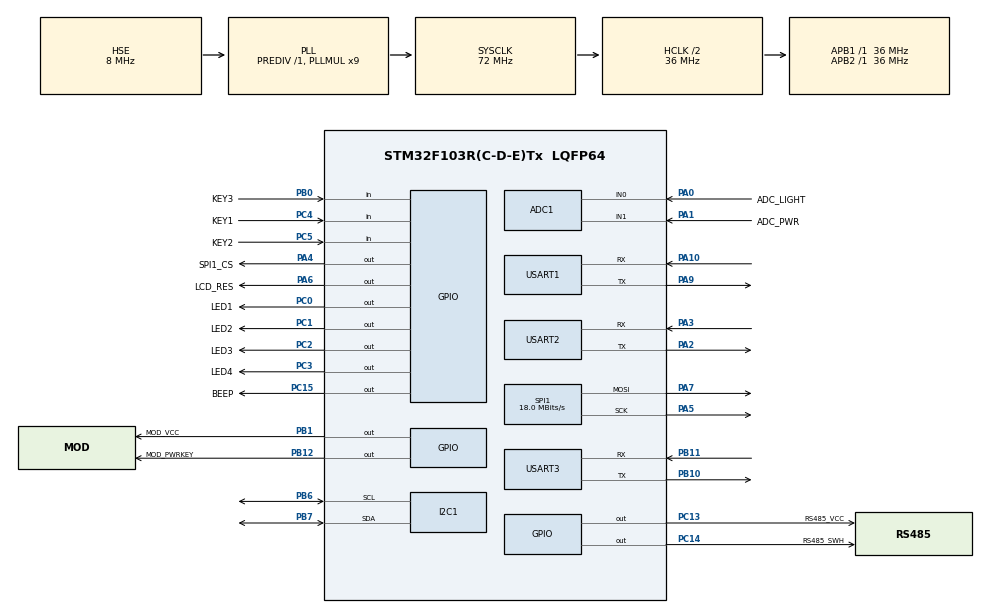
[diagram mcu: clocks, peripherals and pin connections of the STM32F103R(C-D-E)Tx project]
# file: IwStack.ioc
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ADC1.Channel-0\#ChannelRegularConversion=ADC_CHANNEL_1
ADC1.NbrOfConversionFlag=1
ADC1.Rank-0\#ChannelRegularConversion=1
ADC1.SamplingTime-0\#ChannelRegularConversion=ADC_SAMPLETIME_1CYCLE_5
ADC1.master=1
Dma.Request0=USART3_RX
Dma.USART3_RX.0.Direction=DMA_PERIPH_TO_MEMORY
Dma.USART3_RX.0.Instance=DMA1_Channel3
Dma.USART3_RX.0.MemDataAlignment=DMA_MDATAALIGN_BYTE
Dma.USART3_RX.0.MemInc=DMA_MINC_ENABLE
Dma.USART3_RX.0.Mode=DMA_CIRCULAR
Dma.USART3_RX.0.PeriphDataAlignment=DMA_PDATAALIGN_BYTE
Dma.USART3_RX.0.PeriphInc=DMA_PINC_DISABLE
Dma.USART3_RX.0.Priority=DMA_PRIORITY_LOW
FREERTOS.HEAP_NUMBER=3
FREERTOS.INCLUDE_xTaskAbortDelay=1
FREERTOS.Tasks01=myTask_led,25,128,Task01_Led,Default,NULL,Static,myTask_ledBuffer,myTask_ledControlBlock;myTask_net,27,1024,Task03_Net,Default,NULL,Static,myTask_netBuffer,myTask_netControlBlock;myTask_app,28,1024,Task04_App,Default,NULL,Static,myTask_appBuffer,myTask_appControlBlock
FREERTOS.configTOTAL_HEAP_SIZE=0x200
FREERTOS.configUSE_IDLE_HOOK=1
Mcu.Family=STM32F1
Mcu.Name=STM32F103R(C-D-E)Tx
Mcu.Package=LQFP64
NVIC.DMA1_Channel3_IRQn=true\:5\:0\:false\:false\:true\:true\:false\:true
NVIC.PriorityGroup=NVIC_PRIORITYGROUP_4
NVIC.USART3_IRQn=true\:5\:0\:false\:false\:true\:true\:true\:true
PA0-WKUP.GPIO_Label=ADC_LIGHT
PA0-WKUP.Signal=ADCx_IN0
PA1.GPIO_Label=ADC_PWR
PA1.Signal=ADCx_IN1
PA10.Mode=Asynchronous
PA10.Signal=USART1_RX
PA13.Mode=Serial_Wire
PA13.Signal=SYS_JTMS-SWDIO
PA14.Mode=Serial_Wire
PA14.Signal=SYS_JTCK-SWCLK
PA2.Mode=Asynchronous
PA2.Signal=USART2_TX
PA3.Mode=Asynchronous
PA3.Signal=USART2_RX
PA4.GPIO_Label=SPI1_CS
PA4.Signal=GPIO_Output
PA5.Mode=TX_Only_Simplex_Unidirect_Master
PA5.Signal=SPI1_SCK
PA6.GPIO_Label=LCD_RES
PA6.Signal=GPIO_Output
PA7.Mode=TX_Only_Simplex_Unidirect_Master
PA7.Signal=SPI1_MOSI
PA9.Mode=Asynchronous
PA9.Signal=USART1_TX
PB0.GPIO_Label=KEY3
PB0.Signal=GPIO_Input
PB1.GPIO_Label=MOD_VCC
PB1.Signal=GPIO_Output
PB10.Mode=Asynchronous
PB10.Signal=USART3_TX
PB11.Mode=Asynchronous
PB11.Signal=USART3_RX
PB12.GPIO_Label=MOD_PWRKEY
PB12.Signal=GPIO_Output
PB6.Mode=I2C
PB6.Signal=I2C1_SCL
PB7.Mode=I2C
PB7.Signal=I2C1_SDA
PC0.GPIO_Label=LED1
PC0.Signal=GPIO_Output
PC1.GPIO_Label=LED2
PC1.Signal=GPIO_Output
PC13-TAMPER-RTC.GPIO_Label=RS485_VCC
PC13-TAMPER-RTC.Signal=GPIO_Output
PC14-OSC32_IN.GPIO_Label=RS485_SWH
PC14-OSC32_IN.Signal=GPIO_Output
PC15-OSC32_OUT.GPIO_Label=BEEP
PC15-OSC32_OUT.Signal=GPIO_Output
PC2.GPIO_Label=LED3
PC2.Signal=GPIO_Output
PC3.GPIO_Label=LED4
PC3.Signal=GPIO_Output
PC4.GPIO_Label=KEY1
PC4.Signal=GPIO_Input
PC5.GPIO_Label=KEY2
PC5.Signal=GPIO_Input
PD0-OSC_IN.Mode=HSE-External-Oscillator
PD0-OSC_IN.Signal=RCC_OSC_IN
PD1-OSC_OUT.Mode=HSE-External-Oscillator
PD1-OSC_OUT.Signal=RCC_OSC_OUT
ProjectManager.HeapSize=0x4000
ProjectManager.StackSize=0x400
ProjectManager.TargetToolchain=MDK-ARM V5
RCC.ADCPresc=RCC_ADCPCLK2_DIV4
RCC.AHBCLKDivider=RCC_SYSCLK_DIV2
RCC.AHBFreq_Value=36000000
RCC.APB1Freq_Value=36000000
RCC.APB1TimFreq_Value=36000000
RCC.APB2Freq_Value=36000000
RCC.APB2TimFreq_Value=36000000
RCC.HCLKFreq_Value=36000000
RCC.PLLMUL=RCC_PLL_MUL9
RCC.PLLSourceVirtual=RCC_PLLSOURCE_HSE
RCC.SYSCLKFreq_VALUE=72000000
RCC.SYSCLKSource=RCC_SYSCLKSOURCE_PLLCLK
RCC.USBFreq_Value=72000000
SH.ADCx_IN0.0=ADC1_IN0,IN0
SH.ADCx_IN1.0=ADC1_IN1,IN1
SPI1.BaudRatePrescaler=SPI_BAUDRATEPRESCALER_2
SPI1.CalculateBaudRate=18.0 MBits/s
SPI1.Direction=SPI_DIRECTION_2LINES
SPI1.Mode=SPI_MODE_MASTER
SPI1.VirtualType=VM_MASTER
USART1.VirtualMode=VM_ASYNC
USART2.VirtualMode=VM_ASYNC
USART3.VirtualMode=VM_ASYNC
VP_FREERTOS_VS_CMSIS_V2.Mode=CMSIS_V2
board=custom

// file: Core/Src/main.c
/* USER CODE BEGIN Header */
/**
  ******************************************************************************
  * @file           : main.c
  * @brief          : Main program body
  ******************************************************************************
  * @attention
  *
  * <h2><center>&copy; Copyright (c) 2021 STMicroelectronics.
  * All rights reserved.</center></h2>
  *
  * This software component is licensed by ST under BSD 3-Clause license,
  * the "License"; You may not use this file except in compliance with the
  * License. You may obtain a copy of the License at:
  *                        opensource.org/licenses/BSD-3-Clause
  *
  ******************************************************************************
  */
/* USER CODE END Header */
#include "main.h"
#include "cmsis_os.h"

/* USER CODE BEGIN Includes */
#include "uart1_print.h"
#include "chip.h"
/* USER CODE END Includes */

typedef StaticTask_t osStaticThreadDef_t;

ADC_HandleTypeDef hadc1;

I2C_HandleTypeDef hi2c1;

SPI_HandleTypeDef hspi1;

UART_HandleTypeDef huart1;
UART_HandleTypeDef huart2;
UART_HandleTypeDef huart3;
DMA_HandleTypeDef hdma_usart3_rx;

/* Definitions for myTask_led */
osThreadId_t myTask_ledHandle;
uint32_t myTask_ledBuffer[ 128 ];
osStaticThreadDef_t myTask_ledControlBlock;
const osThreadAttr_t myTask_led_attributes = {
  .name = "myTask_led",
  .stack_mem = &myTask_ledBuffer[0],
  .stack_size = sizeof(myTask_ledBuffer),
  .cb_mem = &myTask_ledControlBlock,
  .cb_size = sizeof(myTask_ledControlBlock),
  .priority = (osPriority_t) osPriorityNormal1,
};
/* Definitions for myTask_net */
osThreadId_t myTask_netHandle;
uint32_t myTask_netBuffer[ 1024 ];
osStaticThreadDef_t myTask_netControlBlock;
const osThreadAttr_t myTask_net_attributes = {
  .name = "myTask_net",
  .stack_mem = &myTask_netBuffer[0],
  .stack_size = sizeof(myTask_netBuffer),
  .cb_mem = &myTask_netControlBlock,
  .cb_size = sizeof(myTask_netControlBlock),
  .priority = (osPriority_t) osPriorityNormal3,
};
/* Definitions for myTask_app */
osThreadId_t myTask_appHandle;
uint32_t myTask_appBuffer[ 1024 ];
osStaticThreadDef_t myTask_appControlBlock;
const osThreadAttr_t myTask_app_attributes = {
  .name = "myTask_app",
  .stack_mem = &myTask_appBuffer[0],
  .stack_size = sizeof(myTask_appBuffer),
  .cb_mem = &myTask_appControlBlock,
  .cb_size = sizeof(myTask_appControlBlock),
  .priority = (osPriority_t) osPriorityNormal4,
};

void SystemClock_Config(void);
static void MX_GPIO_Init(void);
static void MX_DMA_Init(void);
static void MX_ADC1_Init(void);
static void MX_I2C1_Init(void);
static void MX_SPI1_Init(void);
static void MX_USART1_UART_Init(void);
static void MX_USART2_UART_Init(void);
static void MX_USART3_UART_Init(void);
void Task01_Led(void *argument);
void Task03_Net(void *argument);
void Task04_App(void *argument);

int main(void)
{

  /* MCU Configuration--------------------------------------------------------*/

  /* Reset of all peripherals, Initializes the Flash interface and the Systick. */
  HAL_Init();

  /* Configure the system clock */
  SystemClock_Config();

  /* Initialize all configured peripherals */
  MX_GPIO_Init();
  MX_DMA_Init();
  MX_ADC1_Init();
  MX_I2C1_Init();
  MX_SPI1_Init();
  MX_USART1_UART_Init();
  MX_USART2_UART_Init();
  MX_USART3_UART_Init();
  /* USER CODE BEGIN 2 */

    USART1_Printf(	"ChipID:%.24s\r\n", CHIP_GetId()	);

  /* USER CODE END 2 */

  /* Init scheduler */
  osKernelInitialize();

  /* Create the thread(s) */
  /* creation of myTask_led */
  myTask_ledHandle = osThreadNew(Task01_Led, NULL, &myTask_led_attributes);

  /* creation of myTask_net */
  myTask_netHandle = osThreadNew(Task03_Net, NULL, &myTask_net_attributes);

  /* creation of myTask_app */
  myTask_appHandle = osThreadNew(Task04_App, NULL, &myTask_app_attributes);

  /* Start scheduler */
  osKernelStart();

  /* We should never get here as control is now taken by the scheduler */
  /* Infinite loop */
    while (1)
    {

    }
}

void SystemClock_Config(void)
{
  RCC_OscInitTypeDef RCC_OscInitStruct = {0};
  RCC_ClkInitTypeDef RCC_ClkInitStruct = {0};
  RCC_PeriphCLKInitTypeDef PeriphClkInit = {0};

  /** Initializes the RCC Oscillators according to the specified parameters
  * in the RCC_OscInitTypeDef structure.
  */
  RCC_OscInitStruct.OscillatorType = RCC_OSCILLATORTYPE_HSE;
  RCC_OscInitStruct.HSEState = RCC_HSE_ON;
  RCC_OscInitStruct.HSEPredivValue = RCC_HSE_PREDIV_DIV1;
  RCC_OscInitStruct.HSIState = RCC_HSI_ON;
  RCC_OscInitStruct.PLL.PLLState = RCC_PLL_ON;
  RCC_OscInitStruct.PLL.PLLSource = RCC_PLLSOURCE_HSE;
  RCC_OscInitStruct.PLL.PLLMUL = RCC_PLL_MUL9;
  if (HAL_RCC_OscConfig(&RCC_OscInitStruct) != HAL_OK)
  {
    Error_Handler();
  }
  /** Initializes the CPU, AHB and APB buses clocks
  */
  RCC_ClkInitStruct.ClockType = RCC_CLOCKTYPE_HCLK|RCC_CLOCKTYPE_SYSCLK
                              |RCC_CLOCKTYPE_PCLK1|RCC_CLOCKTYPE_PCLK2;
  RCC_ClkInitStruct.SYSCLKSource = RCC_SYSCLKSOURCE_PLLCLK;
  RCC_ClkInitStruct.AHBCLKDivider = RCC_SYSCLK_DIV2;
  RCC_ClkInitStruct.APB1CLKDivider = RCC_HCLK_DIV1;
  RCC_ClkInitStruct.APB2CLKDivider = RCC_HCLK_DIV1;

  if (HAL_RCC_ClockConfig(&RCC_ClkInitStruct, FLASH_LATENCY_2) != HAL_OK)
  {
    Error_Handler();
  }
  PeriphClkInit.PeriphClockSelection = RCC_PERIPHCLK_ADC;
  PeriphClkInit.AdcClockSelection = RCC_ADCPCLK2_DIV4;
  if (HAL_RCCEx_PeriphCLKConfig(&PeriphClkInit) != HAL_OK)
  {
    Error_Handler();
  }
}

static void MX_ADC1_Init(void)
{

  ADC_ChannelConfTypeDef sConfig = {0};

  /** Common config
  */
  hadc1.Instance = ADC1;
  hadc1.Init.ScanConvMode = ADC_SCAN_DISABLE;
  hadc1.Init.ContinuousConvMode = DISABLE;
  hadc1.Init.DiscontinuousConvMode = DISABLE;
  hadc1.Init.ExternalTrigConv = ADC_SOFTWARE_START;
  hadc1.Init.DataAlign = ADC_DATAALIGN_RIGHT;
  hadc1.Init.NbrOfConversion = 1;
  if (HAL_ADC_Init(&hadc1) != HAL_OK)
  {
    Error_Handler();
  }
  /** Configure Regular Channel
  */
  sConfig.Channel = ADC_CHANNEL_0;
  sConfig.Rank = ADC_REGULAR_RANK_1;
  sConfig.SamplingTime = ADC_SAMPLETIME_1CYCLE_5;
  if (HAL_ADC_ConfigChannel(&hadc1, &sConfig) != HAL_OK)
  {
    Error_Handler();
  }

}

static void MX_I2C1_Init(void)
{

  hi2c1.Instance = I2C1;
  hi2c1.Init.ClockSpeed = 100000;
  hi2c1.Init.DutyCycle = I2C_DUTYCYCLE_2;
  hi2c1.Init.OwnAddress1 = 0;
  hi2c1.Init.AddressingMode = I2C_ADDRESSINGMODE_7BIT;
  hi2c1.Init.DualAddressMode = I2C_DUALADDRESS_DISABLE;
  hi2c1.Init.OwnAddress2 = 0;
  hi2c1.Init.GeneralCallMode = I2C_GENERALCALL_DISABLE;
  hi2c1.Init.NoStretchMode = I2C_NOSTRETCH_DISABLE;
  if (HAL_I2C_Init(&hi2c1) != HAL_OK)
  {
    Error_Handler();
  }

}

static void MX_SPI1_Init(void)
{

  /* SPI1 parameter configuration*/
  hspi1.Instance = SPI1;
  hspi1.Init.Mode = SPI_MODE_MASTER;
  hspi1.Init.Direction = SPI_DIRECTION_2LINES;
  hspi1.Init.DataSize = SPI_DATASIZE_8BIT;
  hspi1.Init.CLKPolarity = SPI_POLARITY_LOW;
  hspi1.Init.CLKPhase = SPI_PHASE_1EDGE;
  hspi1.Init.NSS = SPI_NSS_SOFT;
  hspi1.Init.BaudRatePrescaler = SPI_BAUDRATEPRESCALER_2;
  hspi1.Init.FirstBit = SPI_FIRSTBIT_MSB;
  hspi1.Init.TIMode = SPI_TIMODE_DISABLE;
  hspi1.Init.CRCCalculation = SPI_CRCCALCULATION_DISABLE;
  hspi1.Init.CRCPolynomial = 10;
  if (HAL_SPI_Init(&hspi1) != HAL_OK)
  {
    Error_Handler();
  }

}

static void MX_USART1_UART_Init(void)
{

  huart1.Instance = USART1;
  huart1.Init.BaudRate = 115200;
  huart1.Init.WordLength = UART_WORDLENGTH_8B;
  huart1.Init.StopBits = UART_STOPBITS_1;
  huart1.Init.Parity = UART_PARITY_NONE;
  huart1.Init.Mode = UART_MODE_TX_RX;
  huart1.Init.HwFlowCtl = UART_HWCONTROL_NONE;
  huart1.Init.OverSampling = UART_OVERSAMPLING_16;
  if (HAL_UART_Init(&huart1) != HAL_OK)
  {
    Error_Handler();
  }

}

static void MX_USART2_UART_Init(void)
{

  huart2.Instance = USART2;
  huart2.Init.BaudRate = 115200;
  huart2.Init.WordLength = UART_WORDLENGTH_8B;
  huart2.Init.StopBits = UART_STOPBITS_1;
  huart2.Init.Parity = UART_PARITY_NONE;
  huart2.Init.Mode = UART_MODE_TX_RX;
  huart2.Init.HwFlowCtl = UART_HWCONTROL_NONE;
  huart2.Init.OverSampling = UART_OVERSAMPLING_16;
  if (HAL_UART_Init(&huart2) != HAL_OK)
  {
    Error_Handler();
  }

}

static void MX_USART3_UART_Init(void)
{

  huart3.Instance = USART3;
  huart3.Init.BaudRate = 115200;
  huart3.Init.WordLength = UART_WORDLENGTH_8B;
  huart3.Init.StopBits = UART_STOPBITS_1;
  huart3.Init.Parity = UART_PARITY_NONE;
  huart3.Init.Mode = UART_MODE_TX_RX;
  huart3.Init.HwFlowCtl = UART_HWCONTROL_NONE;
  huart3.Init.OverSampling = UART_OVERSAMPLING_16;
  if (HAL_UART_Init(&huart3) != HAL_OK)
  {
    Error_Handler();
  }

}

static void MX_DMA_Init(void)
{

  /* DMA controller clock enable */
  __HAL_RCC_DMA1_CLK_ENABLE();

  /* DMA interrupt init */
  /* DMA1_Channel3_IRQn interrupt configuration */
  HAL_NVIC_SetPriority(DMA1_Channel3_IRQn, 5, 0);
  HAL_NVIC_EnableIRQ(DMA1_Channel3_IRQn);

}

static void MX_GPIO_Init(void)
{
  GPIO_InitTypeDef GPIO_InitStruct = {0};

  /* GPIO Ports Clock Enable */
  __HAL_RCC_GPIOC_CLK_ENABLE();
  __HAL_RCC_GPIOD_CLK_ENABLE();
  __HAL_RCC_GPIOA_CLK_ENABLE();
  __HAL_RCC_GPIOB_CLK_ENABLE();

  /*Configure GPIO pin Output Level */
  HAL_GPIO_WritePin(GPIOC, RS485_VCC_Pin|RS485_SWH_Pin|BEEP_Pin|LED1_Pin
                          |LED2_Pin|LED3_Pin|LED4_Pin, GPIO_PIN_RESET);

  /*Configure GPIO pin Output Level */
  HAL_GPIO_WritePin(GPIOA, SPI1_CS_Pin|LCD_RES_Pin, GPIO_PIN_RESET);

  /*Configure GPIO pin Output Level */
  HAL_GPIO_WritePin(GPIOB, MOD_VCC_Pin|MOD_PWRKEY_Pin, GPIO_PIN_RESET);

  /*Configure GPIO pins : RS485_VCC_Pin RS485_SWH_Pin BEEP_Pin LED1_Pin
                           LED2_Pin LED3_Pin LED4_Pin */
  GPIO_InitStruct.Pin = RS485_VCC_Pin|RS485_SWH_Pin|BEEP_Pin|LED1_Pin
                          |LED2_Pin|LED3_Pin|LED4_Pin;
  GPIO_InitStruct.Mode = GPIO_MODE_OUTPUT_PP;
  GPIO_InitStruct.Pull = GPIO_NOPULL;
  GPIO_InitStruct.Speed = GPIO_SPEED_FREQ_LOW;
  HAL_GPIO_Init(GPIOC, &GPIO_InitStruct);

  /*Configure GPIO pins : SPI1_CS_Pin LCD_RES_Pin */
  GPIO_InitStruct.Pin = SPI1_CS_Pin|LCD_RES_Pin;
  GPIO_InitStruct.Mode = GPIO_MODE_OUTPUT_PP;
  GPIO_InitStruct.Pull = GPIO_NOPULL;
  GPIO_InitStruct.Speed = GPIO_SPEED_FREQ_LOW;
  HAL_GPIO_Init(GPIOA, &GPIO_InitStruct);

  /*Configure GPIO pins : KEY1_Pin KEY2_Pin */
  GPIO_InitStruct.Pin = KEY1_Pin|KEY2_Pin;
  GPIO_InitStruct.Mode = GPIO_MODE_INPUT;
  GPIO_InitStruct.Pull = GPIO_NOPULL;
  HAL_GPIO_Init(GPIOC, &GPIO_InitStruct);

  /*Configure GPIO pin : KEY3_Pin */
  GPIO_InitStruct.Pin = KEY3_Pin;
  GPIO_InitStruct.Mode = GPIO_MODE_INPUT;
  GPIO_InitStruct.Pull = GPIO_NOPULL;
  HAL_GPIO_Init(KEY3_GPIO_Port, &GPIO_InitStruct);

  /*Configure GPIO pins : MOD_VCC_Pin MOD_PWRKEY_Pin */
  GPIO_InitStruct.Pin = MOD_VCC_Pin|MOD_PWRKEY_Pin;
  GPIO_InitStruct.Mode = GPIO_MODE_OUTPUT_PP;
  GPIO_InitStruct.Pull = GPIO_NOPULL;
  GPIO_InitStruct.Speed = GPIO_SPEED_FREQ_LOW;
  HAL_GPIO_Init(GPIOB, &GPIO_InitStruct);

}

void Task01_Led(void *argument)
{
  /* USER CODE BEGIN 5 */
    /* Infinite loop */

    extern 	void TASK_Led ( void const * argument );
    TASK_Led ( argument );

  /* USER CODE END 5 */
}

void Task03_Net(void *argument)
{
  /* USER CODE BEGIN Task03_Net */
    /* Infinite loop */

    extern 	void TASK_Net ( void const * argument );
    TASK_Net (  argument );
    ///	while(1)  osDelay ( 200 );

  /* USER CODE END Task03_Net */
}

void Task04_App(void *argument)
{
  /* USER CODE BEGIN Task04_App */
    /* Infinite loop */

    extern 	void TASK_App ( void const * argument );

    TASK_App ( argument );
  /* USER CODE END Task04_App */
}

void Error_Handler(void)
{
    __disable_irq();
    while (1)
    {
    }
}

/************************ (C) COPYRIGHT STMicroelectronics *****END OF FILE****/

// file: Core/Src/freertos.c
/* USER CODE BEGIN Header */
/**
  ******************************************************************************
  * File Name          : freertos.c
  * Description        : Code for freertos applications
  ******************************************************************************
  * @attention
  *
  * <h2><center>&copy; Copyright (c) 2021 STMicroelectronics.
  * All rights reserved.</center></h2>
  *
  * This software component is licensed by ST under Ultimate Liberty license
  * SLA0044, the "License"; You may not use this file except in compliance with
  * the License. You may obtain a copy of the License at:
  *                             www.st.com/SLA0044
  *
  ******************************************************************************
  */
/* USER CODE END Header */

#include "FreeRTOS.h"
#include "task.h"
#include "main.h"

/* Hook prototypes */
void vApplicationIdleHook(void);

/* USER CODE BEGIN 2 */
void vApplicationIdleHook( void )
{
   /* vApplicationIdleHook() will only be called if configUSE_IDLE_HOOK is set
   to 1 in FreeRTOSConfig.h. It will be called on each iteration of the idle
   task. It is essential that code added to this hook function never attempts
   to block in any way (for example, call xQueueReceive() with a block time
   specified, or call vTaskDelay()). If the application makes use of the
   vTaskDelete() API function (as this demo application does) then it is also
   important that vApplicationIdleHook() is permitted to return to its calling
   function, because it is the responsibility of the idle task to clean up
   memory allocated by the kernel to any task that has since been deleted. */
   extern	uint16_t  USART3_Poll ( void );

	USART3_Poll (  );

}
/* USER CODE END 2 */

/************************ (C) COPYRIGHT STMicroelectronics *****END OF FILE****/
